# nrf9120_MLM1 register map
Vendor: Nordic Semiconductor; Series: nrf91; File version: 1
CPU: CM4 r0p1, little endian, MPU, FPU, 3 interrupt priority bits
Registers are 32-bit, read-write, reset 0x0 unless marked. A register's access mark holds for its fields unless they carry their own. Offsets are from the block's base; [hi:lo] are bit positions; lines under a group give offsets from that group; {n}, {i} and the like mark numbered series; 'fields as' and 'values as' point back to an identical list.

## DCNF — Domain Configuration Management
Base 0x40000000; alternate view of PMU_REGULATORS
0x420 CPUID ro — CPU number in the system
  [7:0] CPUID
0x440 EXTPERI0 group — Unspecified
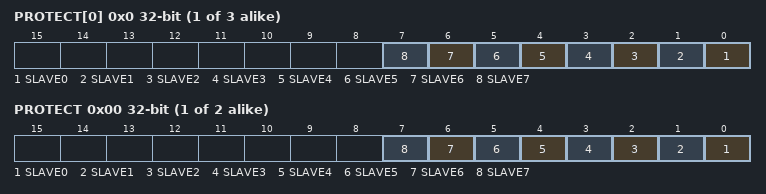
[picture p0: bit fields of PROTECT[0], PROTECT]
  {0x0+4j} PROTECT[{j}] (j=0..2) — Description collection[0]: Control access for Master connected to AMLI master port EXTPERI[0]
    [all] fields
      0=Allowed (Access to slave is possible); 1=Blocked (Access to slave is blocked)
    [n] SLAVE{n} (n=0..7) — Control access to slave {n} of master EXTPERI[0].
{0x44C+4i} EXTPERI1[{i}] (i=0..4) group — Unspecified
  0x00 UNUSED0 — Unspecified
0x460 EXTRAM group — Unspecified
  {0x0+4j} PROTECT[{j}] (j=0..2) — Description collection[0]: Control access from Master connected to AMLI master port EXTRAM[0]
    [all] fields
      values as the fields of EXTPERI0.PROTECT[0]
    [n] SLAVE{n} (n=0..7) — Control access to slave {n} of master EXTRAM[0].
{0x46C+4i} EXTPERI2[{i}] (i=0..4) group — Unspecified
  0x00 UNUSED0 — Unspecified
{0x480+4i} EXTCODE[{i}] (i=0..1) group — Unspecified
  0x00 PROTECT — Description cluster[0]: Control access from Master connected to AMLI master port EXTCODE[0]
    [all] fields
      values as the fields of EXTPERI0.PROTECT[0]
    [n] SLAVE{n} (n=0..7) — Control access to slave {n} of master EXTCODE[0].
{0x488+4i} EXTPERI3[{i}] (i=0..5) group — Unspecified
  0x00 UNUSED0 — Unspecified

## OSCILLATORS — Oscillators control
Base 0x40003000; alternate view of REGULATORS
0x584 ATECLOCK — Analog test bus control for clock modules
  [2:1] PLL — Configure connection of PLL to analog test bus
    0=Disconnected; 1=VC (Connect loop filter voltage to ATB0); 2=Osc32MDiv (Connect 32 MHz divided clock to ATB1); 3=Both (Connect both VC and Osc32MDiv)
0x5C4 XOSC32MACCPL — HFXO bypass mode selection.
  [0] XOSC32MACCPL
    0=normal_bypass_mode (3V square wave on XC1); 1=AC_coupled_bypass_mode (Ac-coupled clipped sine on XC1.)
0x600 BYPASS32KI — Enable or disable bypass of LFCLK crystal oscillator with external clock source
  [0] BYPASS
    0=Disabled (Disable (use with Xtal or low-swing external source)); 1=Enabled (Enable (use with rail-to-rail external source))
0x604 POWERDOWN32KI — Enable/Disable forced power power down of LFXO
  [0] POWERDOWN32KI
    0=DisableForcedOFF (LFXO can be enabled if requested); 1=EnableForcedOFF (LFXO cannot be enabled when requested)
0x608 HFQSTRT
  [0] HFQSTRT
0x60C UNUSED0 — Unspecified
0x610 HFCTRL — Temporary for CLOCK HFCTRL
  [0] HFCTRL
0x614 BYPASS32M — Enable or disable bypass of HFCLK crystal oscillator with external clock source
  fields as BYPASS32KI
0x618 XOSC32MCTRL — Reserved for future use
  [5:0] XOSC32MCTRL
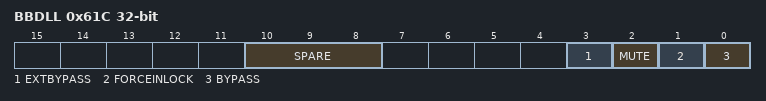
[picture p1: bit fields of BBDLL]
0x61C BBDLL — BBDLL override register in case BBDLL does not behave as expected
  [10:8] SPARE — Spare control signal for BBDLL
  [3] EXTBYPASS — Enable or Disable bypass of BBDLL clock with an external clock provided on GPIO29
    0=Disable (BBDLL is operating normally); 1=Enable (BBDLL output clock is replaced by an external clock provided at GPIO29)
  [2] MUTE — Turn on or off the BBDLL clock output
    0=False (BBDLL clock is not muted); 1=True (BBDLL clock is muted)
  [1] FORCEINLOCK — Control BBDLL Lock behaviour
    0=False (BBDLL Lock signal is provided directly by the BBDLL oscillator); 1=True (BBDLL Lock signal is always forced to one)
  [0] BYPASS — Control BBDLL clock output
    0=False (BBDLL is operating normally); 1=True (BBDLL output clock is replaced by HFCLK)

## PAMLI — Peripheral AHB Multi-Layer Interface
Base 0x40007000
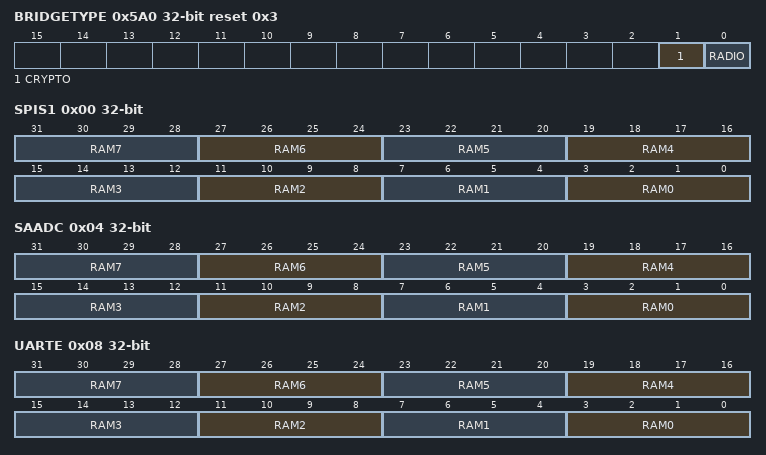
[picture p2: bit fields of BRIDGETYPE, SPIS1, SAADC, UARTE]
0x5A0 BRIDGETYPE reset 0x3 — Select AHB2AHB Sync Bridge Type
  [1] CRYPTO — Select bridge type for CCM, ECB, AAR
    0=Default (Select standard ARM bridge); 1=Nordic (Select Nordic bridge)
  [0] RADIO — Select bridge type for RADIO
    values as CRYPTO
0xE00 RAMPRI group — RAM configurable priority configuration structure
  0x00 SPIS1 — AHB bus master priority register for SPIM1, SPIS1, TWIM1 and TWIS1
    [all] fields
      {v}=Pri{v} (Priority {v}) (v=0..15)
    [4n+3:4n] RAM{n} (n=0..7) — Priority register for RAM AHB slave {n}
  0x04 SAADC — AHB bus master priority register for SAADC
    fields as RAMPRI.SPIS1
  0x08 UARTE — AHB bus master priority register for UARTE
    fields as RAMPRI.SPIS1
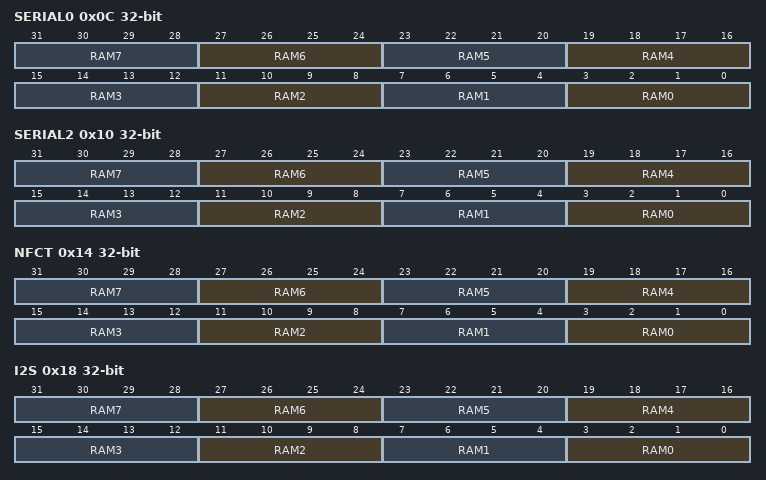
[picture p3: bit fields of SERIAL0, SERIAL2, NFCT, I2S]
  0x0C SERIAL0 — AHB bus master priority register for SPIM0, SPIS0, TWIM0 and TWIS0
    fields as RAMPRI.SPIS1
  0x10 SERIAL2 — AHB bus master priority register for SPIM2 and SPIS2
    fields as RAMPRI.SPIS1
  0x14 NFCT — AHB bus master priority register for NFCT
    fields as RAMPRI.SPIS1
  0x18 I2S — AHB bus master priority register for I2S
    fields as RAMPRI.SPIS1
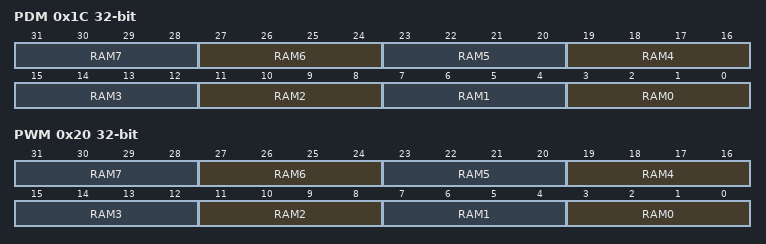
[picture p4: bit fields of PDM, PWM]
  0x1C PDM — AHB bus master priority register for PDM
    fields as RAMPRI.SPIS1
  0x20 PWM — AHB bus master priority register for PWM0, PWM1 and PWM2
    fields as RAMPRI.SPIS1
